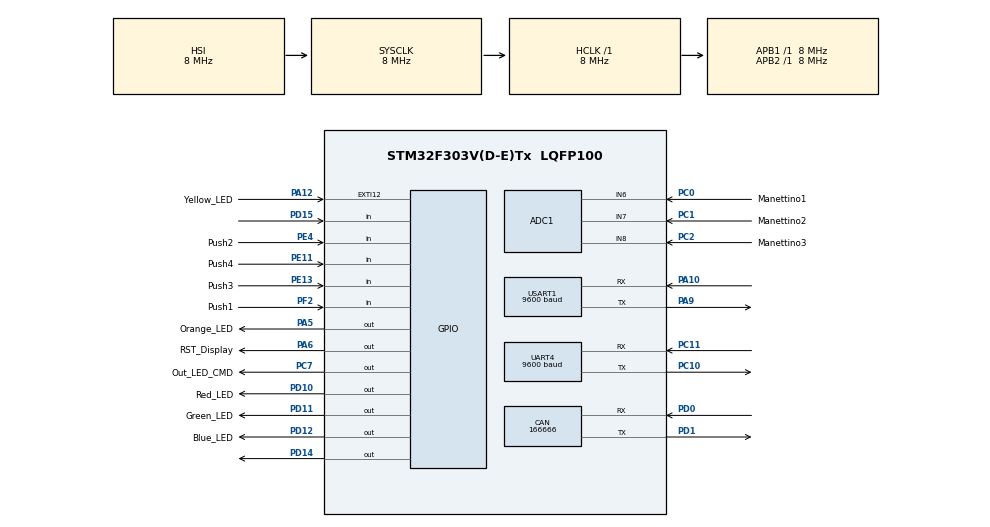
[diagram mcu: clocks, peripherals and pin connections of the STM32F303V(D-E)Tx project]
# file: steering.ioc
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ADC1.Channel-0\#ChannelRegularConversion=ADC_CHANNEL_6
ADC1.ClockPrescaler=ADC_CLOCK_SYNC_PCLK_DIV2
ADC1.NbrOfConversionFlag=1
ADC1.Offset-0\#ChannelRegularConversion=0
ADC1.OffsetNumber-0\#ChannelRegularConversion=ADC_OFFSET_NONE
ADC1.Rank-0\#ChannelRegularConversion=1
ADC1.SamplingTime-0\#ChannelRegularConversion=ADC_SAMPLETIME_1CYCLE_5
ADC1.master=1
CAN.CalculateBaudRate=166666
CAN.CalculateTimeBit=6000
CAN.CalculateTimeQuantum=2000.0
Mcu.Family=STM32F3
Mcu.Name=STM32F303V(D-E)Tx
Mcu.Package=LQFP100
NVIC.PriorityGroup=NVIC_PRIORITYGROUP_4
NVIC.TIM2_IRQn=true\:0\:0\:false\:false\:true\:true\:true\:true
PA10.Mode=Asynchronous
PA10.Signal=USART1_RX
PA12.GPIO_Label=Yellow_LED
PA12.Signal=GPXTI12
PA5.GPIO_Label=Orange_LED
PA5.Signal=GPIO_Output
PA6.GPIO_Label=RST_Display
PA6.Signal=GPIO_Output
PA9.Mode=Asynchronous
PA9.Signal=USART1_TX
PC0.GPIO_Label=Manettino1
PC0.Signal=ADCx_IN6
PC1.GPIO_Label=Manettino2
PC1.Signal=ADCx_IN7
PC10.Mode=Asynchronous
PC10.Signal=UART4_TX
PC11.Mode=Asynchronous
PC11.Signal=UART4_RX
PC2.GPIO_Label=Manettino3
PC2.Signal=ADCx_IN8
PC7.GPIO_Label=Out_LED_CMD
PC7.Signal=GPIO_Output
PD0.Mode=CAN_Activate
PD0.Signal=CAN_RX
PD1.Mode=CAN_Activate
PD1.Signal=CAN_TX
PD10.GPIO_Label=Red_LED
PD10.Signal=GPIO_Output
PD11.GPIO_Label=Green_LED
PD11.Signal=GPIO_Output
PD12.GPIO_Label=Blue_LED
PD12.Signal=GPIO_Output
PD14.Signal=GPIO_Output
PD15.Signal=GPIO_Input
PE11.GPIO_Label=Push4
PE11.Signal=GPIO_Input
PE13.GPIO_Label=Push3
PE13.Signal=GPIO_Input
PE4.GPIO_Label=Push2
PE4.Signal=GPIO_Input
PF2.GPIO_Label=Push1
PF2.Signal=GPIO_Input
ProjectManager.HeapSize=0x200
ProjectManager.StackSize=0x400
ProjectManager.TargetToolchain=Makefile
RCC.AHBFreq_Value=8000000
RCC.APB1Freq_Value=8000000
RCC.APB2Freq_Value=8000000
RCC.CortexFreq_Value=8000000
RCC.HSE_VALUE=8000000
RCC.HSI_VALUE=8000000
RCC.LSE_VALUE=32768
RCC.SYSCLKFreq_VALUE=8000000
RCC.USBFreq_Value=16000000
SH.ADCx_IN6.0=ADC1_IN6,IN6-Single-Ended
SH.ADCx_IN7.0=ADC1_IN7,IN7-Single-Ended
SH.ADCx_IN8.0=ADC1_IN8,IN8-Single-Ended
TIM2.Period=100-1
TIM2.Prescaler=70-1
UART4.BaudRate=9600
USART1.BaudRate=9600
USART1.VirtualMode-Asynchronous=VM_ASYNC
VP_TIM2_VS_ClockSourceINT.Mode=Internal
board=custom

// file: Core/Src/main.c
/* USER CODE BEGIN Header */
/**
  ******************************************************************************
  * @file           : main.c
  * @brief          : Main program body
  ******************************************************************************
  * @attention
  *
  * Copyright (c) 2022 STMicroelectronics.
  * All rights reserved.
  *
  * This software is licensed under terms that can be found in the LICENSE file
  * in the root directory of this software component.
  * If no LICENSE file comes with this software, it is provided AS-IS.
  *
  ******************************************************************************
  */
/* USER CODE END Header */
#include "main.h"

/* USER CODE BEGIN Includes */
#include "Display.h"
/* USER CODE END Includes */

ADC_HandleTypeDef hadc1;

CAN_HandleTypeDef hcan;

TIM_HandleTypeDef htim2;

UART_HandleTypeDef huart4;
UART_HandleTypeDef huart1;

void SystemClock_Config(void);
static void MX_GPIO_Init(void);
static void MX_ADC1_Init(void);
static void MX_CAN_Init(void);
static void MX_TIM2_Init(void);
static void MX_UART4_Init(void);
static void MX_USART1_UART_Init(void);

int main(void)
{

  /* MCU Configuration--------------------------------------------------------*/

  /* Reset of all peripherals, Initializes the Flash interface and the Systick. */
  HAL_Init();

  /* Configure the system clock */
  SystemClock_Config();

  /* Initialize all configured peripherals */
  MX_GPIO_Init();
  MX_ADC1_Init();
  MX_CAN_Init();
  MX_TIM2_Init();
  MX_UART4_Init();
  MX_USART1_UART_Init();

  /* Infinite loop */
  while (1)
  {

  }
}

void SystemClock_Config(void)
{
  RCC_OscInitTypeDef RCC_OscInitStruct = {0};
  RCC_ClkInitTypeDef RCC_ClkInitStruct = {0};
  RCC_PeriphCLKInitTypeDef PeriphClkInit = {0};

  /** Initializes the RCC Oscillators according to the specified parameters
  * in the RCC_OscInitTypeDef structure.
  */
  RCC_OscInitStruct.OscillatorType = RCC_OSCILLATORTYPE_HSI;
  RCC_OscInitStruct.HSIState = RCC_HSI_ON;
  RCC_OscInitStruct.HSICalibrationValue = RCC_HSICALIBRATION_DEFAULT;
  RCC_OscInitStruct.PLL.PLLState = RCC_PLL_NONE;
  if (HAL_RCC_OscConfig(&RCC_OscInitStruct) != HAL_OK)
  {
    Error_Handler();
  }

  /** Initializes the CPU, AHB and APB buses clocks
  */
  RCC_ClkInitStruct.ClockType = RCC_CLOCKTYPE_HCLK|RCC_CLOCKTYPE_SYSCLK
                              |RCC_CLOCKTYPE_PCLK1|RCC_CLOCKTYPE_PCLK2;
  RCC_ClkInitStruct.SYSCLKSource = RCC_SYSCLKSOURCE_HSI;
  RCC_ClkInitStruct.AHBCLKDivider = RCC_SYSCLK_DIV1;
  RCC_ClkInitStruct.APB1CLKDivider = RCC_HCLK_DIV1;
  RCC_ClkInitStruct.APB2CLKDivider = RCC_HCLK_DIV1;

  if (HAL_RCC_ClockConfig(&RCC_ClkInitStruct, FLASH_LATENCY_0) != HAL_OK)
  {
    Error_Handler();
  }
  PeriphClkInit.PeriphClockSelection = RCC_PERIPHCLK_USART1|RCC_PERIPHCLK_UART4
                              |RCC_PERIPHCLK_TIM2;
  PeriphClkInit.Usart1ClockSelection = RCC_USART1CLKSOURCE_PCLK2;
  PeriphClkInit.Uart4ClockSelection = RCC_UART4CLKSOURCE_PCLK1;
  PeriphClkInit.Tim2ClockSelection = RCC_TIM2CLK_HCLK;
  if (HAL_RCCEx_PeriphCLKConfig(&PeriphClkInit) != HAL_OK)
  {
    Error_Handler();
  }
}

static void MX_ADC1_Init(void)
{

  ADC_MultiModeTypeDef multimode = {0};
  ADC_ChannelConfTypeDef sConfig = {0};

  /** Common config
  */
  hadc1.Instance = ADC1;
  hadc1.Init.ClockPrescaler = ADC_CLOCK_SYNC_PCLK_DIV2;
  hadc1.Init.Resolution = ADC_RESOLUTION_12B;
  hadc1.Init.ScanConvMode = ADC_SCAN_DISABLE;
  hadc1.Init.ContinuousConvMode = DISABLE;
  hadc1.Init.DiscontinuousConvMode = DISABLE;
  hadc1.Init.ExternalTrigConvEdge = ADC_EXTERNALTRIGCONVEDGE_NONE;
  hadc1.Init.ExternalTrigConv = ADC_SOFTWARE_START;
  hadc1.Init.DataAlign = ADC_DATAALIGN_RIGHT;
  hadc1.Init.NbrOfConversion = 1;
  hadc1.Init.DMAContinuousRequests = DISABLE;
  hadc1.Init.EOCSelection = ADC_EOC_SINGLE_CONV;
  hadc1.Init.LowPowerAutoWait = DISABLE;
  hadc1.Init.Overrun = ADC_OVR_DATA_OVERWRITTEN;
  if (HAL_ADC_Init(&hadc1) != HAL_OK)
  {
    Error_Handler();
  }

  /** Configure the ADC multi-mode
  */
  multimode.Mode = ADC_MODE_INDEPENDENT;
  if (HAL_ADCEx_MultiModeConfigChannel(&hadc1, &multimode) != HAL_OK)
  {
    Error_Handler();
  }

  /** Configure Regular Channel
  */
  sConfig.Channel = ADC_CHANNEL_6;
  sConfig.Rank = ADC_REGULAR_RANK_1;
  sConfig.SingleDiff = ADC_SINGLE_ENDED;
  sConfig.SamplingTime = ADC_SAMPLETIME_1CYCLE_5;
  sConfig.OffsetNumber = ADC_OFFSET_NONE;
  sConfig.Offset = 0;
  if (HAL_ADC_ConfigChannel(&hadc1, &sConfig) != HAL_OK)
  {
    Error_Handler();
  }

}

static void MX_CAN_Init(void)
{

  hcan.Instance = CAN;
  hcan.Init.Prescaler = 16;
  hcan.Init.Mode = CAN_MODE_NORMAL;
  hcan.Init.SyncJumpWidth = CAN_SJW_1TQ;
  hcan.Init.TimeSeg1 = CAN_BS1_1TQ;
  hcan.Init.TimeSeg2 = CAN_BS2_1TQ;
  hcan.Init.TimeTriggeredMode = DISABLE;
  hcan.Init.AutoBusOff = DISABLE;
  hcan.Init.AutoWakeUp = DISABLE;
  hcan.Init.AutoRetransmission = DISABLE;
  hcan.Init.ReceiveFifoLocked = DISABLE;
  hcan.Init.TransmitFifoPriority = DISABLE;
  if (HAL_CAN_Init(&hcan) != HAL_OK)
  {
    Error_Handler();
  }

}

static void MX_TIM2_Init(void)
{

  TIM_ClockConfigTypeDef sClockSourceConfig = {0};
  TIM_MasterConfigTypeDef sMasterConfig = {0};

  htim2.Instance = TIM2;
  htim2.Init.Prescaler = 70-1;
  htim2.Init.CounterMode = TIM_COUNTERMODE_UP;
  htim2.Init.Period = 100-1;
  htim2.Init.ClockDivision = TIM_CLOCKDIVISION_DIV1;
  htim2.Init.AutoReloadPreload = TIM_AUTORELOAD_PRELOAD_DISABLE;
  if (HAL_TIM_Base_Init(&htim2) != HAL_OK)
  {
    Error_Handler();
  }
  sClockSourceConfig.ClockSource = TIM_CLOCKSOURCE_INTERNAL;
  if (HAL_TIM_ConfigClockSource(&htim2, &sClockSourceConfig) != HAL_OK)
  {
    Error_Handler();
  }
  sMasterConfig.MasterOutputTrigger = TIM_TRGO_RESET;
  sMasterConfig.MasterSlaveMode = TIM_MASTERSLAVEMODE_DISABLE;
  if (HAL_TIMEx_MasterConfigSynchronization(&htim2, &sMasterConfig) != HAL_OK)
  {
    Error_Handler();
  }

}

static void MX_UART4_Init(void)
{

  huart4.Instance = UART4;
  huart4.Init.BaudRate = 9600;
  huart4.Init.WordLength = UART_WORDLENGTH_8B;
  huart4.Init.StopBits = UART_STOPBITS_1;
  huart4.Init.Parity = UART_PARITY_NONE;
  huart4.Init.Mode = UART_MODE_TX_RX;
  huart4.Init.HwFlowCtl = UART_HWCONTROL_NONE;
  huart4.Init.OverSampling = UART_OVERSAMPLING_16;
  huart4.Init.OneBitSampling = UART_ONE_BIT_SAMPLE_DISABLE;
  huart4.AdvancedInit.AdvFeatureInit = UART_ADVFEATURE_NO_INIT;
  if (HAL_UART_Init(&huart4) != HAL_OK)
  {
    Error_Handler();
  }

}

static void MX_USART1_UART_Init(void)
{

  huart1.Instance = USART1;
  huart1.Init.BaudRate = 9600;
  huart1.Init.WordLength = UART_WORDLENGTH_8B;
  huart1.Init.StopBits = UART_STOPBITS_1;
  huart1.Init.Parity = UART_PARITY_NONE;
  huart1.Init.Mode = UART_MODE_TX_RX;
  huart1.Init.HwFlowCtl = UART_HWCONTROL_NONE;
  huart1.Init.OverSampling = UART_OVERSAMPLING_16;
  huart1.Init.OneBitSampling = UART_ONE_BIT_SAMPLE_DISABLE;
  huart1.AdvancedInit.AdvFeatureInit = UART_ADVFEATURE_NO_INIT;
  if (HAL_UART_Init(&huart1) != HAL_OK)
  {
    Error_Handler();
  }

}

static void MX_GPIO_Init(void)
{
  GPIO_InitTypeDef GPIO_InitStruct = {0};

  /* GPIO Ports Clock Enable */
  __HAL_RCC_GPIOE_CLK_ENABLE();
  __HAL_RCC_GPIOC_CLK_ENABLE();
  __HAL_RCC_GPIOF_CLK_ENABLE();
  __HAL_RCC_GPIOA_CLK_ENABLE();
  __HAL_RCC_GPIOD_CLK_ENABLE();

  /*Configure GPIO pin Output Level */
  HAL_GPIO_WritePin(GPIOA, Orange_LED_Pin|RST_Display_Pin, GPIO_PIN_RESET);

  /*Configure GPIO pin Output Level */
  HAL_GPIO_WritePin(GPIOD, Red_LED_Pin|Green_LED_Pin|Blue_LED_Pin|GPIO_PIN_14, GPIO_PIN_RESET);

  /*Configure GPIO pin Output Level */
  HAL_GPIO_WritePin(Out_LED_CMD_GPIO_Port, Out_LED_CMD_Pin, GPIO_PIN_RESET);

  /*Configure GPIO pins : Push2_Pin Push4_Pin Push3_Pin */
  GPIO_InitStruct.Pin = Push2_Pin|Push4_Pin|Push3_Pin;
  GPIO_InitStruct.Mode = GPIO_MODE_INPUT;
  GPIO_InitStruct.Pull = GPIO_NOPULL;
  HAL_GPIO_Init(GPIOE, &GPIO_InitStruct);

  /*Configure GPIO pin : Push1_Pin */
  GPIO_InitStruct.Pin = Push1_Pin;
  GPIO_InitStruct.Mode = GPIO_MODE_INPUT;
  GPIO_InitStruct.Pull = GPIO_NOPULL;
  HAL_GPIO_Init(Push1_GPIO_Port, &GPIO_InitStruct);

  /*Configure GPIO pins : Orange_LED_Pin RST_Display_Pin */
  GPIO_InitStruct.Pin = Orange_LED_Pin|RST_Display_Pin;
  GPIO_InitStruct.Mode = GPIO_MODE_OUTPUT_PP;
  GPIO_InitStruct.Pull = GPIO_NOPULL;
  GPIO_InitStruct.Speed = GPIO_SPEED_FREQ_LOW;
  HAL_GPIO_Init(GPIOA, &GPIO_InitStruct);

  /*Configure GPIO pins : Red_LED_Pin Green_LED_Pin Blue_LED_Pin PD14 */
  GPIO_InitStruct.Pin = Red_LED_Pin|Green_LED_Pin|Blue_LED_Pin|GPIO_PIN_14;
  GPIO_InitStruct.Mode = GPIO_MODE_OUTPUT_PP;
  GPIO_InitStruct.Pull = GPIO_NOPULL;
  GPIO_InitStruct.Speed = GPIO_SPEED_FREQ_LOW;
  HAL_GPIO_Init(GPIOD, &GPIO_InitStruct);

  /*Configure GPIO pin : PD15 */
  GPIO_InitStruct.Pin = GPIO_PIN_15;
  GPIO_InitStruct.Mode = GPIO_MODE_INPUT;
  GPIO_InitStruct.Pull = GPIO_NOPULL;
  HAL_GPIO_Init(GPIOD, &GPIO_InitStruct);

  /*Configure GPIO pin : Out_LED_CMD_Pin */
  GPIO_InitStruct.Pin = Out_LED_CMD_Pin;
  GPIO_InitStruct.Mode = GPIO_MODE_OUTPUT_PP;
  GPIO_InitStruct.Pull = GPIO_NOPULL;
  GPIO_InitStruct.Speed = GPIO_SPEED_FREQ_LOW;
  HAL_GPIO_Init(Out_LED_CMD_GPIO_Port, &GPIO_InitStruct);

  /*Configure GPIO pin : Yellow_LED_Pin */
  GPIO_InitStruct.Pin = Yellow_LED_Pin;
  GPIO_InitStruct.Mode = GPIO_MODE_IT_RISING;
  GPIO_InitStruct.Pull = GPIO_NOPULL;
  HAL_GPIO_Init(Yellow_LED_GPIO_Port, &GPIO_InitStruct);

}

void Error_Handler(void)
{
  __disable_irq();
  while (1)
  {
  }
}
